AUTOSAR XML (schema 4-2-2)
package /ComponentTypes
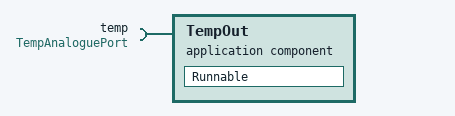
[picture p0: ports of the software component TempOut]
  application sw component type TempOut
    require port temp: required-com-specs=[{data-element=tempIn, init-value=0}, {data-element=tempOut, init-value=0}], required-interface=TempAnaloguePort
    behavior TempOut_InternalBehavior: data-type-mapping=tempMapSet
      data received event DRT_Runnable_TempAnaloguePort_tempIn: start-on-event=Runnable, data=temp.tempIn
      data received event DRT_Runnable_TempAnaloguePort_tempOut: start-on-event=Runnable, data=temp.tempOut
      runnable Runnable
        data-receive-point-by-arguments:
          access REC_TempAnaloguePort_tempIn: accessed-variable=temp.tempIn
          access REC_TempAnaloguePort_tempOut: accessed-variable=temp.tempOut
  swc implementation TempOut_Implementation: behavior=TempOut_InternalBehavior
